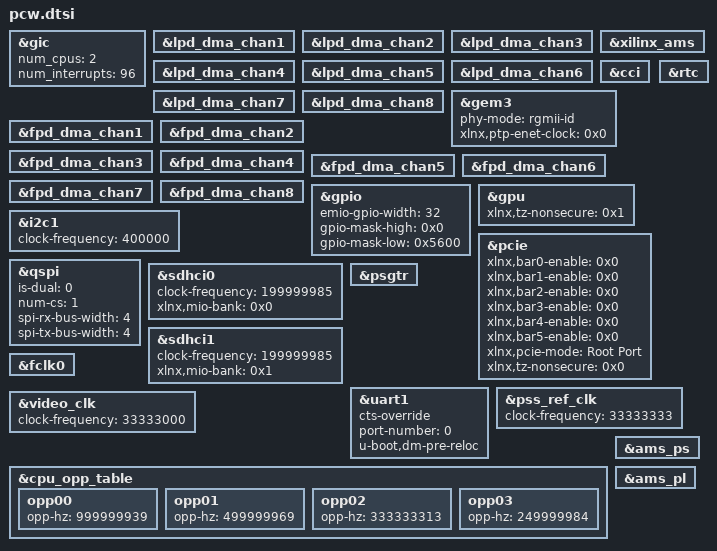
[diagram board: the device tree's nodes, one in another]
/*
 * CAUTION: This file is automatically generated by Xilinx.
 * Version:  
 * Today is: Fri May 31 07:39:59 2024
 */


&gic {
	num_cpus = <2>;
	num_interrupts = <96>;
};
&lpd_dma_chan1 {
	status = "okay";
};
&lpd_dma_chan2 {
	status = "okay";
};
&lpd_dma_chan3 {
	status = "okay";
};
&lpd_dma_chan4 {
	status = "okay";
};
&lpd_dma_chan5 {
	status = "okay";
};
&lpd_dma_chan6 {
	status = "okay";
};
&lpd_dma_chan7 {
	status = "okay";
};
&lpd_dma_chan8 {
	status = "okay";
};
&xilinx_ams {
	status = "okay";
};
&cci {
	status = "okay";
};
&gem3 {
	phy-mode = "rgmii-id";
	status = "okay";
	xlnx,ptp-enet-clock = <0x0>;
};
&fpd_dma_chan1 {
	status = "okay";
};
&fpd_dma_chan2 {
	status = "okay";
};
&fpd_dma_chan3 {
	status = "okay";
};
&fpd_dma_chan4 {
	status = "okay";
};
&fpd_dma_chan5 {
	status = "okay";
};
&fpd_dma_chan6 {
	status = "okay";
};
&fpd_dma_chan7 {
	status = "okay";
};
&fpd_dma_chan8 {
	status = "okay";
};
&gpio {
	emio-gpio-width = <32>;
	gpio-mask-high = <0x0>;
	gpio-mask-low = <0x5600>;
	status = "okay";
};
&gpu {
	status = "okay";
	xlnx,tz-nonsecure = <0x1>;
};
&i2c1 {
	clock-frequency = <400000>;
	status = "okay";
};
&pcie {
	status = "okay";
	xlnx,bar0-enable = <0x0>;
	xlnx,bar1-enable = <0x0>;
	xlnx,bar2-enable = <0x0>;
	xlnx,bar3-enable = <0x0>;
	xlnx,bar4-enable = <0x0>;
	xlnx,bar5-enable = <0x0>;
	xlnx,pcie-mode = "Root Port";
	xlnx,tz-nonsecure = <0x0>;
};
&qspi {
	is-dual = <0>;
	num-cs = <1>;
	spi-rx-bus-width = <4>;
	spi-tx-bus-width = <4>;
	status = "okay";
};
&rtc {
	status = "okay";
};
&sdhci0 {
	clock-frequency = <199999985>;
	status = "okay";
	xlnx,mio-bank = <0x0>;
};
&sdhci1 {
	clock-frequency = <199999985>;
	status = "okay";
	xlnx,mio-bank = <0x1>;
};
&psgtr {
	status = "okay";
};
&uart1 {
	cts-override ;
	device_type = "serial";
	port-number = <0>;
	status = "okay";
	u-boot,dm-pre-reloc ;
};
&fclk0 {
	status = "okay";
};
&pss_ref_clk {
	clock-frequency = <33333333>;
};
&video_clk {
	clock-frequency = <33333000>;
};
&cpu_opp_table {
	opp00 {
		opp-hz = /bits/ 64 <999999939>;
	};
	opp01 {
		opp-hz = /bits/ 64 <499999969>;
	};
	opp02 {
		opp-hz = /bits/ 64 <333333313>;
	};
	opp03 {
		opp-hz = /bits/ 64 <249999984>;
	};
};
&ams_ps {
	status = "okay";
};
&ams_pl {
	status = "okay";
};
